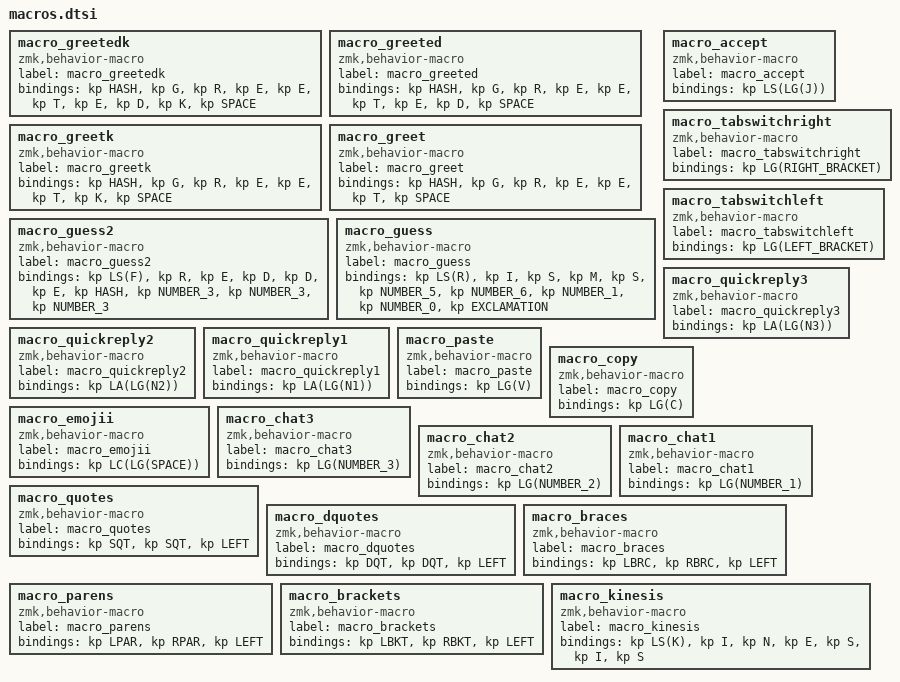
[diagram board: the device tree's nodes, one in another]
macro_greetedk: macro_greetedk{
compatible = "zmk,behavior-macro";
label = "macro_greetedk";
#binding-cells = <0>;
bindings = <&kp HASH>, <&kp G>, <&kp R>, <&kp E>, <&kp E>, <&kp T>, <&kp E>, <&kp D>, <&kp K>, <&kp SPACE>;
};
macro_greeted: macro_greeted{
compatible = "zmk,behavior-macro";
label = "macro_greeted";
#binding-cells = <0>;
bindings = <&kp HASH>, <&kp G>, <&kp R>, <&kp E>, <&kp E>, <&kp T>, <&kp E>, <&kp D>, <&kp SPACE>;
};
macro_greetk: macro_greetk{
compatible = "zmk,behavior-macro";
label = "macro_greetk";
#binding-cells = <0>;
bindings = <&kp HASH>, <&kp G>, <&kp R>, <&kp E>, <&kp E>, <&kp T>, <&kp K>, <&kp SPACE>;
};
macro_greet: macro_greet{
compatible = "zmk,behavior-macro";
label = "macro_greet";
#binding-cells = <0>;
bindings = <&kp HASH>, <&kp G>, <&kp R>, <&kp E>, <&kp E>, <&kp T>, <&kp SPACE>;
};
macro_guess2: macro_guess2{
compatible = "zmk,behavior-macro";
label = "macro_guess2";
#binding-cells = <0>;
bindings = <&kp LS(F)>, <&kp R>, <&kp E>, <&kp D>, <&kp D>, <&kp E>, <&kp HASH>, <&kp NUMBER_3>, <&kp NUMBER_3>, <&kp NUMBER_3>;
};
macro_guess: macro_guess{
compatible = "zmk,behavior-macro";
label = "macro_guess";
#binding-cells = <0>;
bindings = <&kp LS(R)>, <&kp I>, <&kp S>, <&kp M>, <&kp S>, <&kp NUMBER_5>, <&kp NUMBER_6>, <&kp NUMBER_1>, <&kp NUMBER_0>, <&kp EXCLAMATION>;
};
macro_accept: macro_accept{
compatible = "zmk,behavior-macro";
label = "macro_accept";
#binding-cells = <0>;
bindings = <&kp LS(LG(J))>;
};
macro_tabswitchright: macro_tabswitchright{
compatible = "zmk,behavior-macro";
label = "macro_tabswitchright";
#binding-cells = <0>;
bindings = <&kp LG(RIGHT_BRACKET)>;
};
macro_tabswitchleft: macro_tabswitchleft{
compatible = "zmk,behavior-macro";
label = "macro_tabswitchleft";
#binding-cells = <0>;
bindings = <&kp LG(LEFT_BRACKET)>;
};
macro_quickreply3: macro_quickreply3{
compatible = "zmk,behavior-macro";
label = "macro_quickreply3";
#binding-cells = <0>;
bindings = <&kp LA(LG(N3))>;
};
macro_quickreply2: macro_quickreply2{
compatible = "zmk,behavior-macro";
label = "macro_quickreply2";
#binding-cells = <0>;
bindings = <&kp LA(LG(N2))>;
};
macro_quickreply1: macro_quickreply1{
compatible = "zmk,behavior-macro";
label = "macro_quickreply1";
#binding-cells = <0>;
bindings = <&kp LA(LG(N1))>;
};
macro_paste: macro_paste{
compatible = "zmk,behavior-macro";
label = "macro_paste";
#binding-cells = <0>;
bindings = <&kp LG(V)>;
};
macro_copy: macro_copy{
compatible = "zmk,behavior-macro";
label = "macro_copy";
#binding-cells = <0>;
bindings = <&kp LG(C)>;
};
macro_emojii: macro_emojii{
compatible = "zmk,behavior-macro";
label = "macro_emojii";
#binding-cells = <0>;
bindings = <&kp LC(LG(SPACE))>;
};
macro_chat3: macro_chat3{
compatible = "zmk,behavior-macro";
label = "macro_chat3";
#binding-cells = <0>;
bindings = <&kp LG(NUMBER_3)>;
};
macro_chat2: macro_chat2{
compatible = "zmk,behavior-macro";
label = "macro_chat2";
#binding-cells = <0>;
bindings = <&kp LG(NUMBER_2)>;
};
macro_chat1: macro_chat1{
compatible = "zmk,behavior-macro";
label = "macro_chat1";
#binding-cells = <0>;
bindings = <&kp LG(NUMBER_1)>;
};
macro_quotes: macro_quotes{
compatible = "zmk,behavior-macro";
label = "macro_quotes";
#binding-cells = <0>;
bindings = <&kp SQT>, <&kp SQT>, <&kp LEFT>;
};
macro_dquotes: macro_dquotes{
compatible = "zmk,behavior-macro";
label = "macro_dquotes";
#binding-cells = <0>;
bindings = <&kp DQT>, <&kp DQT>, <&kp LEFT>;
};
macro_braces: macro_braces{
compatible = "zmk,behavior-macro";
label = "macro_braces";
#binding-cells = <0>;
bindings = <&kp LBRC>, <&kp RBRC>, <&kp LEFT>;
};
macro_parens: macro_parens{
compatible = "zmk,behavior-macro";
label = "macro_parens";
#binding-cells = <0>;
bindings = <&kp LPAR>, <&kp RPAR>, <&kp LEFT>;
};
macro_brackets: macro_brackets{
compatible = "zmk,behavior-macro";
label = "macro_brackets";
#binding-cells = <0>;
bindings = <&kp LBKT>, <&kp RBKT>, <&kp LEFT>;
};
macro_kinesis: macro_kinesis{
compatible = "zmk,behavior-macro";
label = "macro_kinesis";
#binding-cells = <0>;
bindings = <&kp LS(K)>, <&kp I>, <&kp N>, <&kp E>, <&kp S>, <&kp I>, <&kp S>;
};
